AUTOSAR XML (schema 4.0)
package /Demo_Components
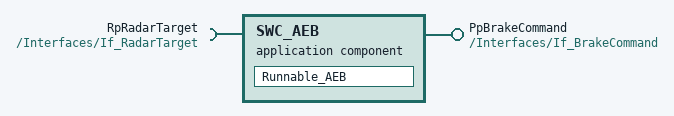
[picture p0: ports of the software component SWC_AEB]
  application sw component type SWC_AEB
    provide port PpBrakeCommand: provided-interface=/Interfaces/If_BrakeCommand
    require port RpRadarTarget: required-interface=/Interfaces/If_RadarTarget
    behavior IB_SWC_AEB
      runnable Runnable_AEB: symbol=C_Function_CalculateTTC
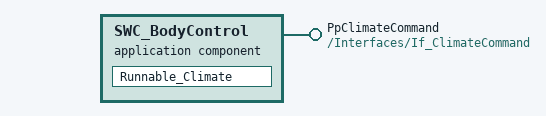
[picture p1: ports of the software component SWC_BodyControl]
  application sw component type SWC_BodyControl
    provide port PpClimateCommand: provided-interface=/Interfaces/If_ClimateCommand
    behavior IB_SWC_BodyControl
      runnable Runnable_Climate: symbol=C_Function_CabinClimateControl
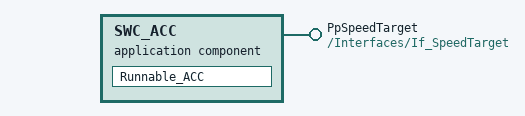
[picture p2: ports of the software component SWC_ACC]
  application sw component type SWC_ACC
    provide port PpSpeedTarget: provided-interface=/Interfaces/If_SpeedTarget
    behavior IB_SWC_ACC
      runnable Runnable_ACC: symbol=C_Function_AdaptiveCruiseSpeed
